# AT32WB415 register map
Vendor: Keil; Series: AT32WB415; File version: 1.0
CPU: CM4 r0p1, little endian, no MPU, FPU, 4 interrupt priority bits
Registers are 32-bit, read-write, reset 0x0 unless marked. A register's access mark holds for its fields unless they carry their own. Offsets are from the block's base; [hi:lo] are bit positions.

## SPI2 — Serial peripheral interface
Base 0x40003800
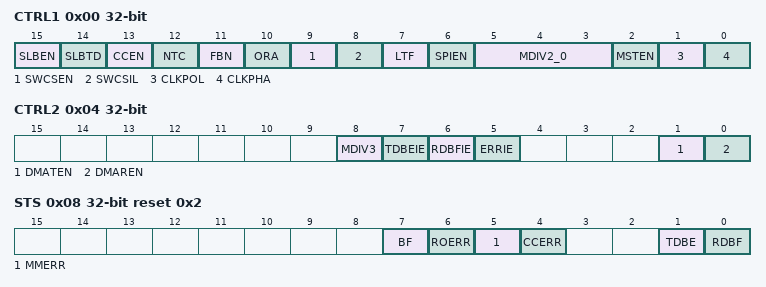
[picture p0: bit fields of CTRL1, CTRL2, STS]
0x00 CTRL1 — control register 1
  [15] SLBEN — Single line bidirectional half-duplex enable
    on read: 0=Disabled (Single line bidirectional half-duplex is disabled); 1=Enabled (Single line bidirectional half-duplex is enabled) | on write: 0=Disable (Single line bidirectional half-duplex disable); 1=Enable (Single line bidirectional half-duplex enable)
  [14] SLBTD — Single line bidirectional half-duplex transmission direction
    0=Receive-only mode; 1=Transmit-only mode
  [13] CCEN — CRC calculation enable
    on read: 0=Disabled (CRC calculation is disabled); 1=Enabled (CRC calculation is enabled) | on write: 0=Disable (CRC calculation disable); 1=Enable (CRC calculation enable)
  [12] NTC — Next transmission CRC
    0=Normal (Next transmitted data is the normal value); 1=CRC (Next transmitted data is CRC value)
  [11] FBN — frame bit num
    0=bit8 (8-bit data frame); 1=bit16 (16-bit data frame)
  [10] ORA — Only receive active
    0=RxTx (Transmission and reception); 1=Receive-only mode
  [9] SWCSEN — Software CS enable
    on read: 0=Disabled (Software CS is disabled); 1=Enabled (Software CS is enabled) | on write: 0=Disable (Software CS disable); 1=Enable (Software CS enable)
  [8] SWCSIL — Software CS internal level
    0=Low (Low level); 1=High level
  [7] LTF — LSB transmit first
    0=MSB (Most significant bit first); 1=LSB (Least significant bit first)
  [6] SPIEN — SPI enable
    on read: 0=Disabled (SPI is disabled); 1=Enabled (SPI is enabled) | on write: 0=Disable (SPI disable); 1=Enable (SPI enable)
  [5:3] MDIV2_0 — Master clock frequency division bit2-0
  [2] MSTEN — Master enable
    0=Slave (Master is disabled (Slave)"); 1=Master is enabled"
  [1] CLKPOL — Clock polarity
    0=Low (Low level); 1=High level
  [0] CLKPHA — Clock phase
    0=First (Data capture starts from the first clock edge); 1=Second (Data capture starts from the second clock edge)
0x04 CTRL2 — control register 2
  [8] MDIV3 — Master clock frequency division bit3
  [7] TDBEIE — Transmit data buffer empty interrupt enable
    on read: 0=Disabled (Transmit data buffer empty interrupt is disabled); 1=Enabled (Transmit data buffer empty interrupt is enabled) | on write: 0=Disable (Transmit data buffer empty interrupt disable); 1=Enable (Transmit data buffer empty interrupt enable)
  [6] RDBFIE — Receive data buffer full interrupt enable
    on read: 0=Disabled (Receive data buffer full interrupt is disabled); 1=Enabled (Receive data buffer full interrupt is enabled) | on write: 0=Disable (Receive data buffer full interrupt disable); 1=Enable (Receive data buffer full interrupt enable)
  [5] ERRIE — Error interrupt enable
    on read: 0=Disabled (Error interrupt is disabled); 1=Enabled (Error interrupt is enabled) | on write: 0=Disable (Error interrupt disable); 1=Enable (Error interrupt enable)
  [1] DMATEN — DMA transmit enable
    on read: 0=Disabled (DMA transmit is disabled); 1=Enabled (DMA transmit is enabled) | on write: 0=Disable (DMA transmit disable); 1=Enable (DMA transmit enable)
  [0] DMAREN — DMA receive enable
    on read: 0=Disabled (DMA receive is disabled); 1=Enabled (DMA receive is enabled) | on write: 0=Disable (DMA receive disable); 1=Enable (DMA receive enable)
0x08 STS reset 0x2 — status register
  [7] BF ro — Busy flag
    0=Idle (SPI is not busy); 1=Busy (SPI is busy)
  [6] ROERR ro — Receiver overflow error
    0=NoError (No overflow error); 1=Overflow error occurs
  [5] MMERR ro — Master mode error
    0=NoError (No mode error); 1=Error (Mode error occurs)
  [4] CCERR write-0-clears — CRC calculation error
    on read: 0=NoError (No CRC error); 1=Error (CRC error occurs) | on write: 0=Clear CRC error
  [1] TDBE ro — Transmit data buffer empty
    0=NotEmpty (Transmit data buffer is not empty); 1=Empty (Transmit data buffer is empty)
  [0] RDBF ro — Receive data buffer full
    0=NotFull (Receive data buffer is not full); 1=Full (Receive data buffer is full)
0x0C DT — data register
  [15:0] DT — Data value
0x10 CPOLY reset 0x7 — CRC polynomial register
  [15:0] CPOLY — CRC polynomial
0x14 RCRC ro — Receive CRC register
  [15:0] RCRC — Receive CRC
0x18 TCRC ro — Transmit CRC register
  [15:0] TCRC — Transmit CRC
